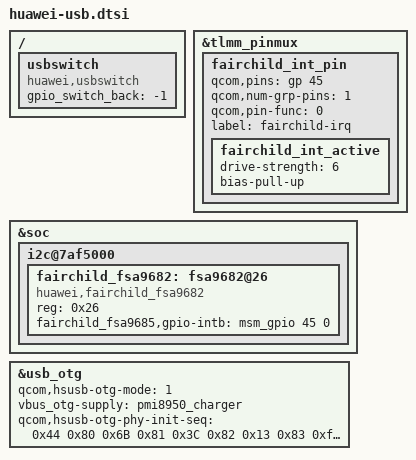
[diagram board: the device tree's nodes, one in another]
/{
	usbswitch: usbswitch {
		compatible = "huawei,usbswitch";
		gpio_switch_back = "-1";
		status = "ok";
	};
};

&tlmm_pinmux {

		fairchild_int_pin {
			qcom,pins = <&gp 45>;
			qcom,num-grp-pins = <1>;
			qcom,pin-func = <0>;
			label = "fairchild-irq";
			fairchild_int_active: fairchild_int_active {
				drive-strength = <6>;
				bias-pull-up;
			};
		};
};
&soc {
	i2c@7af5000{
		fairchild_fsa9682: fsa9682@26 {
			compatible = "huawei,fairchild_fsa9682";
			reg = <0x26>;
			fairchild_fsa9685,gpio-intb = <&msm_gpio 45 0>;
			status = "ok";
		};
	};
};

&usb_otg {
	qcom,hsusb-otg-mode = <1>;
	vbus_otg-supply = <&pmi8950_charger>;
	qcom,hsusb-otg-phy-init-seq =
		<0x44 0x80 0x6B 0x81 0x3C 0x82 0x13 0x83 0xffffffff>;
};
